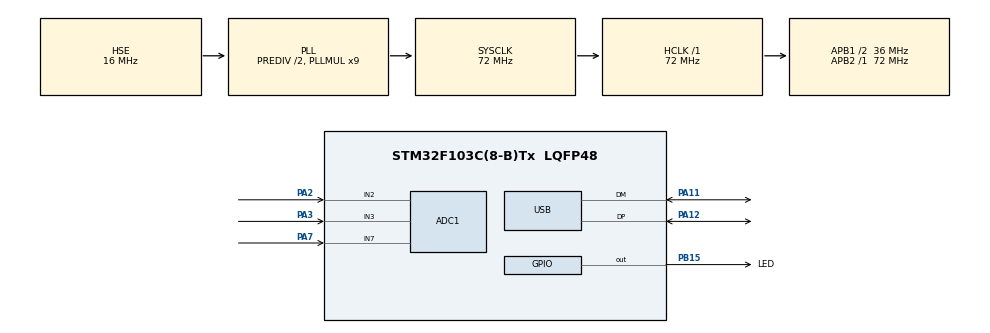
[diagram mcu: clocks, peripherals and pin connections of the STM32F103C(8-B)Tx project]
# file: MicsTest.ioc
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ADC1.Channel-0\#ChannelRegularConversion=ADC_CHANNEL_2
ADC1.Channel-1\#ChannelRegularConversion=ADC_CHANNEL_3
ADC1.Channel-2\#ChannelRegularConversion=ADC_CHANNEL_7
ADC1.ContinuousConvMode=ENABLE
ADC1.NbrOfConversion=3
ADC1.NbrOfConversionFlag=1
ADC1.Rank-0\#ChannelRegularConversion=1
ADC1.Rank-1\#ChannelRegularConversion=2
ADC1.Rank-2\#ChannelRegularConversion=3
ADC1.SamplingTime-0\#ChannelRegularConversion=ADC_SAMPLETIME_1CYCLE_5
ADC1.SamplingTime-1\#ChannelRegularConversion=ADC_SAMPLETIME_1CYCLE_5
ADC1.SamplingTime-2\#ChannelRegularConversion=ADC_SAMPLETIME_1CYCLE_5
ADC1.master=1
Dma.ADC1.0.Direction=DMA_PERIPH_TO_MEMORY
Dma.ADC1.0.Instance=DMA1_Channel1
Dma.ADC1.0.MemDataAlignment=DMA_MDATAALIGN_HALFWORD
Dma.ADC1.0.MemInc=DMA_MINC_ENABLE
Dma.ADC1.0.Mode=DMA_CIRCULAR
Dma.ADC1.0.PeriphDataAlignment=DMA_PDATAALIGN_HALFWORD
Dma.ADC1.0.PeriphInc=DMA_PINC_DISABLE
Dma.ADC1.0.Priority=DMA_PRIORITY_LOW
Dma.Request0=ADC1
Mcu.Family=STM32F1
Mcu.Name=STM32F103C(8-B)Tx
Mcu.Package=LQFP48
NVIC.DMA1_Channel1_IRQn=true\:0\:0\:false\:false\:true\:false\:true\:true
NVIC.PriorityGroup=NVIC_PRIORITYGROUP_4
NVIC.USB_HP_CAN1_TX_IRQn=true\:0\:0\:false\:false\:true\:true\:true\:true
NVIC.USB_LP_CAN1_RX0_IRQn=true\:0\:0\:false\:false\:true\:true\:true\:true
PA11.Mode=Device
PA11.Signal=USB_DM
PA12.Mode=Device
PA12.Signal=USB_DP
PA13.Mode=Trace_Asynchronous_SW
PA13.Signal=SYS_JTMS-SWDIO
PA14.Mode=Trace_Asynchronous_SW
PA14.Signal=SYS_JTCK-SWCLK
PA2.Signal=ADCx_IN2
PA3.Signal=ADCx_IN3
PA7.Signal=ADCx_IN7
PB15.GPIO_Label=LED
PB15.Signal=GPIO_Output
PB3.Mode=Trace_Asynchronous_SW
PB3.Signal=SYS_JTDO-TRACESWO
PD0-OSC_IN.Mode=HSE-External-Oscillator
PD0-OSC_IN.Signal=RCC_OSC_IN
PD1-OSC_OUT.Mode=HSE-External-Oscillator
PD1-OSC_OUT.Signal=RCC_OSC_OUT
ProjectManager.HeapSize=0x200
ProjectManager.StackSize=0x400
ProjectManager.TargetToolchain=STM32CubeIDE
RCC.ADCPresc=RCC_ADCPCLK2_DIV6
RCC.AHBFreq_Value=72000000
RCC.APB1CLKDivider=RCC_HCLK_DIV2
RCC.APB1Freq_Value=36000000
RCC.APB1TimFreq_Value=72000000
RCC.APB2Freq_Value=72000000
RCC.APB2TimFreq_Value=72000000
RCC.HCLKFreq_Value=72000000
RCC.HSEDivPLL=RCC_HSE_PREDIV_DIV2
RCC.HSE_VALUE=16000000
RCC.PLLMUL=RCC_PLL_MUL9
RCC.PLLSourceVirtual=RCC_PLLSOURCE_HSE
RCC.SYSCLKFreq_VALUE=72000000
RCC.SYSCLKSource=RCC_SYSCLKSOURCE_PLLCLK
RCC.USBFreq_Value=48000000
RCC.USBPrescaler=RCC_USBCLKSOURCE_PLL_DIV1_5
SH.ADCx_IN2.0=ADC1_IN2,IN2
SH.ADCx_IN3.0=ADC1_IN3,IN3
SH.ADCx_IN7.0=ADC1_IN7,IN7
board=custom

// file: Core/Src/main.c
/* USER CODE BEGIN Header */
/**
  ******************************************************************************
  * @file           : main.c
  * @brief          : Main program body
  ******************************************************************************
  * @attention
  *
  * Copyright (c) 2025 STMicroelectronics.
  * All rights reserved.
  *
  * This software is licensed under terms that can be found in the LICENSE file
  * in the root directory of this software component.
  * If no LICENSE file comes with this software, it is provided AS-IS.
  *
  ******************************************************************************
  */
/* USER CODE END Header */
#include "main.h"

/* USER CODE BEGIN Includes */
#include "usb.h"
/* USER CODE END Includes */

ADC_HandleTypeDef hadc1;
DMA_HandleTypeDef hdma_adc1;

PCD_HandleTypeDef hpcd_USB_FS;

void SystemClock_Config(void);
static void MX_GPIO_Init(void);
static void MX_DMA_Init(void);
static void MX_ADC1_Init(void);
static void MX_USB_PCD_Init(void);

/* USER CODE BEGIN 0 */

#include "stdio.h"
int _write(int file, char *ptr, int len) {
	for (int i = 0; i < len; i++) {
		ITM_SendChar(*ptr++);
	}
	return len;
}

uint16_t sound[SOUND_ITEMS/2];
/* USER CODE END 0 */

int main(void)
{

  /* MCU Configuration--------------------------------------------------------*/

  /* Reset of all peripherals, Initializes the Flash interface and the Systick. */
  HAL_Init();

  /* Configure the system clock */
  SystemClock_Config();

  /* Initialize all configured peripherals */
  MX_GPIO_Init();
  MX_DMA_Init();
  MX_ADC1_Init();
  MX_USB_PCD_Init();
  /* USER CODE BEGIN 2 */
  printf("Starting...\n");
  HAL_ADC_Start_DMA(&hadc1, (uint32_t*)sound, SOUND_ITEMS/2);
  /* USER CODE END 2 */

  /* Infinite loop */
  /* USER CODE BEGIN WHILE */
  while (1)
  {
//	  HAL_GPIO_TogglePin(LED_GPIO_Port, LED_Pin);
    /* USER CODE END WHILE */

    /* USER CODE BEGIN 3 */
	  HAL_Delay(500);
  }
  /* USER CODE END 3 */
}

void SystemClock_Config(void)
{
  RCC_OscInitTypeDef RCC_OscInitStruct = {0};
  RCC_ClkInitTypeDef RCC_ClkInitStruct = {0};
  RCC_PeriphCLKInitTypeDef PeriphClkInit = {0};

  /** Initializes the RCC Oscillators according to the specified parameters
  * in the RCC_OscInitTypeDef structure.
  */
  RCC_OscInitStruct.OscillatorType = RCC_OSCILLATORTYPE_HSE;
  RCC_OscInitStruct.HSEState = RCC_HSE_ON;
  RCC_OscInitStruct.HSEPredivValue = RCC_HSE_PREDIV_DIV2;
  RCC_OscInitStruct.HSIState = RCC_HSI_ON;
  RCC_OscInitStruct.PLL.PLLState = RCC_PLL_ON;
  RCC_OscInitStruct.PLL.PLLSource = RCC_PLLSOURCE_HSE;
  RCC_OscInitStruct.PLL.PLLMUL = RCC_PLL_MUL9;
  if (HAL_RCC_OscConfig(&RCC_OscInitStruct) != HAL_OK)
  {
    Error_Handler();
  }

  /** Initializes the CPU, AHB and APB buses clocks
  */
  RCC_ClkInitStruct.ClockType = RCC_CLOCKTYPE_HCLK|RCC_CLOCKTYPE_SYSCLK
                              |RCC_CLOCKTYPE_PCLK1|RCC_CLOCKTYPE_PCLK2;
  RCC_ClkInitStruct.SYSCLKSource = RCC_SYSCLKSOURCE_PLLCLK;
  RCC_ClkInitStruct.AHBCLKDivider = RCC_SYSCLK_DIV1;
  RCC_ClkInitStruct.APB1CLKDivider = RCC_HCLK_DIV2;
  RCC_ClkInitStruct.APB2CLKDivider = RCC_HCLK_DIV1;

  if (HAL_RCC_ClockConfig(&RCC_ClkInitStruct, FLASH_LATENCY_2) != HAL_OK)
  {
    Error_Handler();
  }
  PeriphClkInit.PeriphClockSelection = RCC_PERIPHCLK_ADC|RCC_PERIPHCLK_USB;
  PeriphClkInit.AdcClockSelection = RCC_ADCPCLK2_DIV6;
  PeriphClkInit.UsbClockSelection = RCC_USBCLKSOURCE_PLL_DIV1_5;
  if (HAL_RCCEx_PeriphCLKConfig(&PeriphClkInit) != HAL_OK)
  {
    Error_Handler();
  }
}

static void MX_ADC1_Init(void)
{

  ADC_ChannelConfTypeDef sConfig = {0};

  /** Common config
  */
  hadc1.Instance = ADC1;
  hadc1.Init.ScanConvMode = ADC_SCAN_ENABLE;
  hadc1.Init.ContinuousConvMode = ENABLE;
  hadc1.Init.DiscontinuousConvMode = DISABLE;
  hadc1.Init.ExternalTrigConv = ADC_SOFTWARE_START;
  hadc1.Init.DataAlign = ADC_DATAALIGN_RIGHT;
  hadc1.Init.NbrOfConversion = 3;
  if (HAL_ADC_Init(&hadc1) != HAL_OK)
  {
    Error_Handler();
  }

  /** Configure Regular Channel
  */
  sConfig.Channel = ADC_CHANNEL_2;
  sConfig.Rank = ADC_REGULAR_RANK_1;
  sConfig.SamplingTime = ADC_SAMPLETIME_1CYCLE_5;
  if (HAL_ADC_ConfigChannel(&hadc1, &sConfig) != HAL_OK)
  {
    Error_Handler();
  }

  /** Configure Regular Channel
  */
  sConfig.Channel = ADC_CHANNEL_3;
  sConfig.Rank = ADC_REGULAR_RANK_2;
  if (HAL_ADC_ConfigChannel(&hadc1, &sConfig) != HAL_OK)
  {
    Error_Handler();
  }

  /** Configure Regular Channel
  */
  sConfig.Channel = ADC_CHANNEL_7;
  sConfig.Rank = ADC_REGULAR_RANK_3;
  if (HAL_ADC_ConfigChannel(&hadc1, &sConfig) != HAL_OK)
  {
    Error_Handler();
  }

}

static void MX_USB_PCD_Init(void)
{

  hpcd_USB_FS.Instance = USB;
  hpcd_USB_FS.Init.dev_endpoints = 8;
  hpcd_USB_FS.Init.speed = PCD_SPEED_FULL;
  hpcd_USB_FS.Init.low_power_enable = DISABLE;
  hpcd_USB_FS.Init.lpm_enable = DISABLE;
  hpcd_USB_FS.Init.battery_charging_enable = DISABLE;
  if (HAL_PCD_Init(&hpcd_USB_FS) != HAL_OK)
  {
    Error_Handler();
  }
  /* USER CODE BEGIN USB_Init 2 */
  USB_Start_M3();
  /* USER CODE END USB_Init 2 */

}

static void MX_DMA_Init(void)
{

  /* DMA controller clock enable */
  __HAL_RCC_DMA1_CLK_ENABLE();

  /* DMA interrupt init */
  /* DMA1_Channel1_IRQn interrupt configuration */
  HAL_NVIC_SetPriority(DMA1_Channel1_IRQn, 0, 0);
  HAL_NVIC_EnableIRQ(DMA1_Channel1_IRQn);

}

static void MX_GPIO_Init(void)
{
  GPIO_InitTypeDef GPIO_InitStruct = {0};

  /* GPIO Ports Clock Enable */
  __HAL_RCC_GPIOD_CLK_ENABLE();
  __HAL_RCC_GPIOA_CLK_ENABLE();
  __HAL_RCC_GPIOB_CLK_ENABLE();

  /*Configure GPIO pin Output Level */
  HAL_GPIO_WritePin(LED_GPIO_Port, LED_Pin, GPIO_PIN_RESET);

  /*Configure GPIO pin : LED_Pin */
  GPIO_InitStruct.Pin = LED_Pin;
  GPIO_InitStruct.Mode = GPIO_MODE_OUTPUT_PP;
  GPIO_InitStruct.Pull = GPIO_NOPULL;
  GPIO_InitStruct.Speed = GPIO_SPEED_FREQ_LOW;
  HAL_GPIO_Init(LED_GPIO_Port, &GPIO_InitStruct);

}

void Error_Handler(void)
{
  __disable_irq();
  while (1)
  {
  }
}
